# km_mailbox_km: IP-XACT component
VLNV tenstorrent.com:ocah:km_mailbox_km:1.0

## Address spaces and blocks
km_mailbox_km_mmap.km_mailbox_km: base 'h0, range 'h1c, width 32

## Registers
Registers are 32-bit, access per field, reset 0x0 unless marked. A register's access mark holds for its fields unless they carry their own. Offsets are from the block's base; lines under a group give offsets from that group; [hi:lo] are bit positions; {n}, {i} and the like mark numbered series; 'fields as' and 'values as' point back to an identical list; <NAME> marks a mode.

## km_mailbox_km_mmap.km_mailbox_km — Register interface for KM CPU to access mailbox (write to outbound FIFO, read from inbound FIFO)
Base 0x00000000
0x00 KM_WRITE_DATA wo — Write data to outbound FIFO (KM→SEP messages)
  [31:0] data — 32-bit data word to write to outbound FIFO
0x04 KM_WRITE_SEPARATOR — Write 1 to set message separator on next outbound (KM→SEP) write. Cleared by hardware when that write completes.
  [0] set rw — Write 1 to set message separator on next outbound write. Cleared by hardware when that write completes.
0x08 KM_READ_DATA ro — Read data from inbound FIFO (SEP→KM messages)
  [31:0] data — 32-bit data word read from inbound FIFO
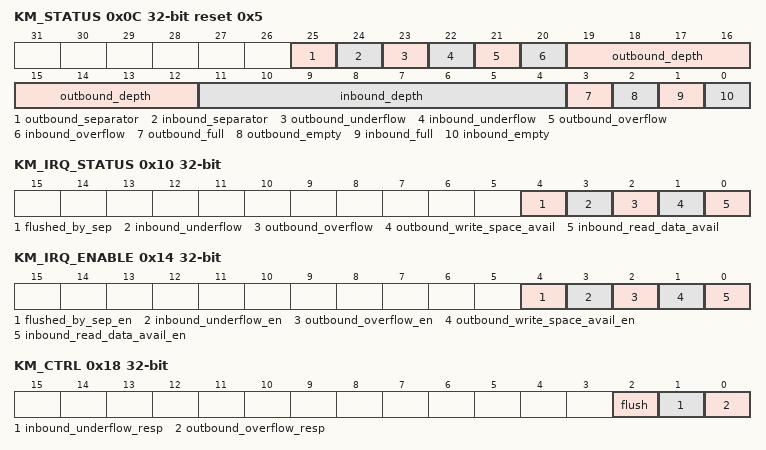
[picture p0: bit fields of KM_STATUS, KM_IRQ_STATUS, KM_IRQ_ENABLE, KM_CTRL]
0x0C KM_STATUS reset 0x5 — FIFO status information
  [25] outbound_separator ro — Message separator: 1 if the last word read from outbound FIFO had the separator bit set (last word of message). Read-only, not sticky.
  [24] inbound_separator ro — Message separator: 1 if the last word read from inbound FIFO had the separator bit set (last word of message). Read-only, not sticky.
  [23] outbound_underflow rw write-1-clears — Outbound FIFO underflow detected (read attempted when empty). Sticky, write 1 to clear.
  [22] inbound_underflow rw write-1-clears — Inbound FIFO underflow detected (read attempted when empty). Sticky, write 1 to clear.
  [21] outbound_overflow rw write-1-clears — Outbound FIFO overflow detected (write attempted when full). Sticky, write 1 to clear.
  [20] inbound_overflow rw write-1-clears — Inbound FIFO overflow detected (write attempted when full). Sticky, write 1 to clear.
  [19:12] outbound_depth ro — Outbound FIFO fill level (number of words in FIFO)
  [11:4] inbound_depth ro — Inbound FIFO fill level (number of words in FIFO)
  [3] outbound_full ro — Outbound FIFO is full (cannot write more data)
  [2] outbound_empty ro — Outbound FIFO is empty (no data available for SEP to read)
  [1] inbound_full ro — Inbound FIFO is full
  [0] inbound_empty ro — Inbound FIFO is empty (no data available for KM to read)
0x10 KM_IRQ_STATUS — Interrupt status register
  [4] flushed_by_sep rw write-1-clears — SEP performed a mailbox flush. Sticky, write 1 to clear.
  [3] inbound_underflow rw write-1-clears — Inbound FIFO underflow detected. Sticky, write 1 to clear.
  [2] outbound_overflow rw write-1-clears — Outbound FIFO overflow detected. Sticky, write 1 to clear.
  [1] outbound_write_space_avail ro — Outbound FIFO has space available for KM to write (level-sensitive). 1 = space available, 0 = full.
  [0] inbound_read_data_avail ro — Inbound FIFO has data available for KM to read (level-sensitive). 1 = data available, 0 = empty.
0x14 KM_IRQ_ENABLE — Interrupt enable register for KM CPU
  [4] flushed_by_sep_en rw — Enable interrupt to KM when SEP performs a mailbox flush
  [3] inbound_underflow_en rw — Enable interrupt to KM when inbound FIFO underflow is detected
  [2] outbound_overflow_en rw — Enable interrupt to KM when outbound FIFO overflow is detected
  [1] outbound_write_space_avail_en rw — Enable interrupt to KM when outbound FIFO has space available (KM->SEP messages)
  [0] inbound_read_data_avail_en rw — Enable interrupt to KM when inbound FIFO has data available (SEP->KM messages)
0x18 KM_CTRL — Control register for mailbox behavior configuration
  [2] flush rw — Write 1 to flush all mailbox FIFOs (inbound and outbound). Cleared by hardware when flush completes.
  [1] inbound_underflow_resp rw — Response type for inbound FIFO underflow: 0=SLVERR (default), 1=OKAY
  [0] outbound_overflow_resp rw — Response type for outbound FIFO overflow: 0=SLVERR (default), 1=OKAY

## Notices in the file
SPDX-License-Identifier: Apache-2.0
SPDX-FileCopyrightText: 2026 Tenstorrent USA, Inc.
